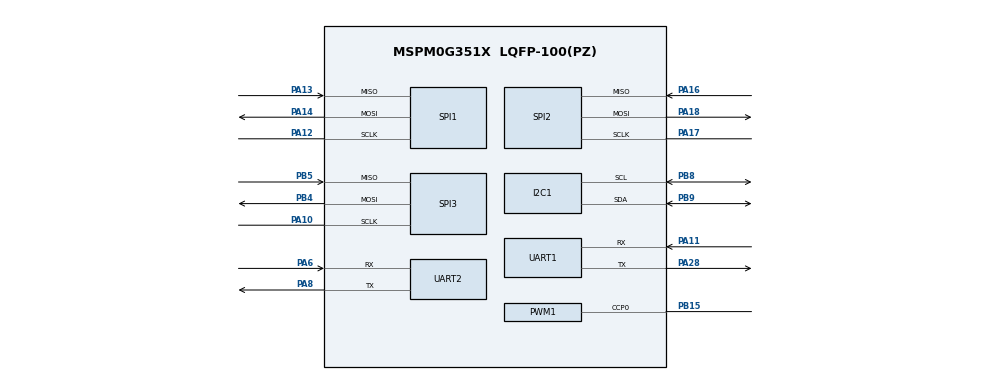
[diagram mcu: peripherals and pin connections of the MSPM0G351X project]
/**
 * @cliArgs --device "MSPM0G351X" --part "Default" --package "LQFP-100(PZ)" --product "mspm0_sdk@2.10.00.04"
 * @versions {"tool":"1.26.2+4477"}
 */

/**
 * Import the modules used in this configuration.
 */
const GPIO   = scripting.addModule("/ti/driverlib/GPIO", {}, false);
const GPIO1  = GPIO.addInstance();
const GPIO2  = GPIO.addInstance();
const GPIO3  = GPIO.addInstance();
const GPIO4  = GPIO.addInstance();
const GPIO5  = GPIO.addInstance();
const GPIO6  = GPIO.addInstance();
const GPIO7  = GPIO.addInstance();
const GPIO8  = GPIO.addInstance();
const GPIO9  = GPIO.addInstance();
const GPIO10 = GPIO.addInstance();
const GPIO11 = GPIO.addInstance();
const I2C    = scripting.addModule("/ti/driverlib/I2C", {}, false);
const I2C1   = I2C.addInstance();
const PWM    = scripting.addModule("/ti/driverlib/PWM", {}, false);
const PWM1   = PWM.addInstance();
const RTCB   = scripting.addModule("/ti/driverlib/RTCB");
const SPI    = scripting.addModule("/ti/driverlib/SPI", {}, false);
const SPI1   = SPI.addInstance();
const SPI2   = SPI.addInstance();
const SPI3   = SPI.addInstance();
const SYSCTL = scripting.addModule("/ti/driverlib/SYSCTL");
const TIMER  = scripting.addModule("/ti/driverlib/TIMER", {}, false);
const TIMER1 = TIMER.addInstance();
const TIMER2 = TIMER.addInstance();
const UART   = scripting.addModule("/ti/driverlib/UART", {}, false);
const UART1  = UART.addInstance();
const UART2  = UART.addInstance();

/**
 * Write custom configuration values to the imported modules.
 */
GPIO1.$name                                 = "BATTERY_CS";
GPIO1.associatedPins[0].$name               = "CS1";
GPIO1.associatedPins[0].initialValue        = "SET";
GPIO1.associatedPins[0].assignedPort        = "PORTB";
GPIO1.associatedPins[0].assignedPortSegment = "Upper";
GPIO1.associatedPins[0].assignedPin         = "19";

const Board = scripting.addModule("/ti/driverlib/Board", {}, false);

GPIO2.$name                                 = "SELECT_CONVERTER";
GPIO2.associatedPins[0].internalResistor    = "PULL_DOWN";
GPIO2.associatedPins[0].$name               = "PIN_0";
GPIO2.associatedPins[0].direction           = "INPUT";
GPIO2.associatedPins[0].assignedPort        = "PORTB";
GPIO2.associatedPins[0].assignedPortSegment = "Lower";
GPIO2.associatedPins[0].assignedPin         = "2";

GPIO3.$name                                 = "RECT_CS";
GPIO3.associatedPins[0].$name               = "CS2";
GPIO3.associatedPins[0].initialValue        = "SET";
GPIO3.associatedPins[0].assignedPort        = "PORTA";
GPIO3.associatedPins[0].assignedPin         = "15";
GPIO3.associatedPins[0].assignedPortSegment = "Lower";

GPIO4.$name                                 = "BAT_ALERT";
GPIO4.associatedPins[0].$name               = "PIN_1";
GPIO4.associatedPins[0].direction           = "INPUT";
GPIO4.associatedPins[0].ioStructure         = "SD";
GPIO4.associatedPins[0].assignedPort        = "PORTB";
GPIO4.associatedPins[0].interruptEn         = true;
GPIO4.associatedPins[0].polarity            = "FALL";
GPIO4.associatedPins[0].internalResistor    = "PULL_UP";
GPIO4.associatedPins[0].assignedPortSegment = "Upper";
GPIO4.associatedPins[0].assignedPin         = "18";

GPIO5.$name                              = "RECT_ALERT";
GPIO5.port                               = "PORTB";
GPIO5.portSegment                        = "Upper";
GPIO5.associatedPins[0].direction        = "INPUT";
GPIO5.associatedPins[0].ioStructure      = "SD";
GPIO5.associatedPins[0].interruptEn      = true;
GPIO5.associatedPins[0].polarity         = "FALL";
GPIO5.associatedPins[0].internalResistor = "PULL_UP";
GPIO5.associatedPins[0].assignedPin      = "17";
GPIO5.associatedPins[0].$name            = "PIN_17";

GPIO6.$name                                 = "DUMP_LOAD_RELAY";
GPIO6.associatedPins[0].assignedPortSegment = "Lower";
GPIO6.associatedPins[0].assignedPort        = "PORTA";
GPIO6.associatedPins[0].assignedPin         = "7";
GPIO6.associatedPins[0].$name               = "IN1";

GPIO7.$name                                 = "LCD";
GPIO7.associatedPins.create(6);
GPIO7.associatedPins[0].$name               = "RS";
GPIO7.associatedPins[0].assignedPort        = "PORTA";
GPIO7.associatedPins[0].assignedPortSegment = "Upper";
GPIO7.associatedPins[0].assignedPin         = "31";
GPIO7.associatedPins[1].$name               = "EN";
GPIO7.associatedPins[1].assignedPort        = "PORTA";
GPIO7.associatedPins[1].assignedPortSegment = "Lower";
GPIO7.associatedPins[1].assignedPin         = "3";
GPIO7.associatedPins[2].$name               = "D4";
GPIO7.associatedPins[2].assignedPort        = "PORTA";
GPIO7.associatedPins[2].assignedPortSegment = "Lower";
GPIO7.associatedPins[2].assignedPin         = "4";
GPIO7.associatedPins[3].$name               = "D5";
GPIO7.associatedPins[3].assignedPort        = "PORTA";
GPIO7.associatedPins[3].assignedPortSegment = "Lower";
GPIO7.associatedPins[3].assignedPin         = "5";
GPIO7.associatedPins[4].$name               = "D6";
GPIO7.associatedPins[4].assignedPortSegment = "Lower";
GPIO7.associatedPins[4].assignedPort        = "PORTB";
GPIO7.associatedPins[4].assignedPin         = "0";
GPIO7.associatedPins[5].$name               = "D7";
GPIO7.associatedPins[5].assignedPort        = "PORTB";
GPIO7.associatedPins[5].assignedPortSegment = "Lower";
GPIO7.associatedPins[5].assignedPin         = "1";

GPIO8.$name                                 = "UI_BUTTON";
GPIO8.associatedPins.create(4);
GPIO8.associatedPins[0].$name               = "NEXT";
GPIO8.associatedPins[0].direction           = "INPUT";
GPIO8.associatedPins[0].internalResistor    = "PULL_DOWN";
GPIO8.associatedPins[0].interruptEn         = true;
GPIO8.associatedPins[0].polarity            = "RISE";
GPIO8.associatedPins[0].assignedPort        = "PORTB";
GPIO8.associatedPins[0].assignedPortSegment = "Upper";
GPIO8.associatedPins[0].assignedPin         = "27";
GPIO8.associatedPins[1].$name               = "PREV";
GPIO8.associatedPins[1].direction           = "INPUT";
GPIO8.associatedPins[1].internalResistor    = "PULL_DOWN";
GPIO8.associatedPins[1].interruptEn         = true;
GPIO8.associatedPins[1].polarity            = "RISE";
GPIO8.associatedPins[1].assignedPort        = "PORTB";
GPIO8.associatedPins[1].assignedPortSegment = "Upper";
GPIO8.associatedPins[1].assignedPin         = "26";
GPIO8.associatedPins[2].internalResistor    = "PULL_DOWN";
GPIO8.associatedPins[2].$name               = "START_STOP";
GPIO8.associatedPins[2].direction           = "INPUT";
GPIO8.associatedPins[2].interruptEn         = true;
GPIO8.associatedPins[2].polarity            = "RISE";
GPIO8.associatedPins[2].assignedPort        = "PORTB";
GPIO8.associatedPins[2].assignedPortSegment = "Upper";
GPIO8.associatedPins[2].assignedPin         = "25";
GPIO8.associatedPins[3].$name               = "RECORD";
GPIO8.associatedPins[3].direction           = "INPUT";
GPIO8.associatedPins[3].internalResistor    = "PULL_DOWN";
GPIO8.associatedPins[3].interruptEn         = true;
GPIO8.associatedPins[3].polarity            = "RISE";
GPIO8.associatedPins[3].assignedPort        = "PORTA";
GPIO8.associatedPins[3].assignedPortSegment = "Upper";
GPIO8.associatedPins[3].assignedPin         = "25";

GPIO9.$name                                 = "UI_LED";
GPIO9.associatedPins.create(5);
GPIO9.associatedPins[0].$name               = "START";
GPIO9.associatedPins[0].assignedPort        = "PORTA";
GPIO9.associatedPins[0].assignedPortSegment = "Upper";
GPIO9.associatedPins[0].assignedPin         = "27";
GPIO9.associatedPins[1].$name               = "STOP";
GPIO9.associatedPins[1].assignedPort        = "PORTA";
GPIO9.associatedPins[1].assignedPortSegment = "Upper";
GPIO9.associatedPins[1].assignedPin         = "26";
GPIO9.associatedPins[2].$name               = "IS_RECORDING";
GPIO9.associatedPins[2].assignedPort        = "PORTA";
GPIO9.associatedPins[2].assignedPortSegment = "Upper";
GPIO9.associatedPins[2].assignedPin         = "24";
GPIO9.associatedPins[3].$name               = "TURBINE_OK";
GPIO9.associatedPins[3].assignedPort        = "PORTB";
GPIO9.associatedPins[3].assignedPortSegment = "Upper";
GPIO9.associatedPins[3].assignedPin         = "23";
GPIO9.associatedPins[4].$name               = "LOAD_UI_OK";
GPIO9.associatedPins[4].assignedPort        = "PORTB";
GPIO9.associatedPins[4].assignedPortSegment = "Upper";
GPIO9.associatedPins[4].assignedPin         = "24";

GPIO10.$name                                 = "SD_CS";
GPIO10.associatedPins[0].$name               = "CS";
GPIO10.associatedPins[0].initialValue        = "SET";
GPIO10.associatedPins[0].assignedPortSegment = "Lower";
GPIO10.associatedPins[0].assignedPort        = "PORTB";
GPIO10.associatedPins[0].assignedPin         = "3";

GPIO11.$name                                 = "BATTERY_RELAY";
GPIO11.associatedPins[0].assignedPort        = "PORTB";
GPIO11.associatedPins[0].assignedPortSegment = "Lower";
GPIO11.associatedPins[0].assignedPin         = "12";
GPIO11.associatedPins[0].$name               = "IN2";

I2C1.basicEnableController             = true;
I2C1.basicControllerBusSpeed           = 400000;
I2C1.$name                             = "MCP45HV51";
I2C1.peripheral.sdaPin.$assign         = "PB9";
I2C1.peripheral.sclPin.$assign         = "PB8";
I2C1.sdaPinConfig.hideOutputInversion  = scripting.forceWrite(false);
I2C1.sdaPinConfig.onlyInternalResistor = scripting.forceWrite(false);
I2C1.sdaPinConfig.passedPeripheralType = scripting.forceWrite("Digital");
I2C1.sdaPinConfig.$name                = "ti_driverlib_gpio_GPIOPinGeneric16";
I2C1.sdaPinConfig.enableConfig         = true;
I2C1.sdaPinConfig.internalResistor     = "PULL_UP";
I2C1.sclPinConfig.hideOutputInversion  = scripting.forceWrite(false);
I2C1.sclPinConfig.onlyInternalResistor = scripting.forceWrite(false);
I2C1.sclPinConfig.passedPeripheralType = scripting.forceWrite("Digital");
I2C1.sclPinConfig.$name                = "ti_driverlib_gpio_GPIOPinGeneric17";
I2C1.sclPinConfig.enableConfig         = true;
I2C1.sclPinConfig.internalResistor     = "PULL_UP";

PWM1.$name                      = "PWM_0";
PWM1.timerCount                 = 320;
PWM1.ccIndex                    = [0];
PWM1.pwmMode                    = "EDGE_ALIGN_UP";
PWM1.PWM_CHANNEL_0.$name        = "ti_driverlib_pwm_PWMTimerCC0";
PWM1.PWM_CHANNEL_0.dutyCycle    = 30;
PWM1.ccp0PinConfig.$name        = "ti_driverlib_gpio_GPIOPinGeneric5";
PWM1.peripheral.ccp0Pin.$assign = "PB15";

RTCB.calYear     = 2026;
RTCB.calMonth    = "5";
RTCB.calDOM      = 4;
RTCB.calDOW      = "4";
RTCB.enableClock = true;

SPI1.enableDMAEvent1                    = false;
SPI1.enableDMAEvent2                    = false;
SPI1.spiClkSrc                          = "MFCLK";
SPI1.spiClkDiv                          = "4";
SPI1.frameFormat                        = "MOTO3";
SPI1.chipSelect                         = [];
SPI1.phase                              = "1";
SPI1.targetBitRate                      = 500000;
SPI1.rxFifoThreshold                    = "DL_SPI_RX_FIFO_LEVEL_ONE_FRAME";
SPI1.txFifoThreshold                    = "DL_SPI_TX_FIFO_LEVEL_ONE_FRAME";
SPI1.$name                              = "INA229_RECT_SPI0";
SPI1.sclkPinConfig.direction            = scripting.forceWrite("OUTPUT");
SPI1.sclkPinConfig.onlyInternalResistor = scripting.forceWrite(false);
SPI1.sclkPinConfig.passedPeripheralType = scripting.forceWrite("Digital");
SPI1.sclkPinConfig.$name                = "ti_driverlib_gpio_GPIOPinGeneric0";
SPI1.mosiPinConfig.direction            = scripting.forceWrite("OUTPUT");
SPI1.mosiPinConfig.hideOutputInversion  = scripting.forceWrite(false);
SPI1.mosiPinConfig.onlyInternalResistor = scripting.forceWrite(false);
SPI1.mosiPinConfig.passedPeripheralType = scripting.forceWrite("Digital");
SPI1.mosiPinConfig.$name                = "ti_driverlib_gpio_GPIOPinGeneric1";
SPI1.misoPinConfig.onlyInternalResistor = scripting.forceWrite(false);
SPI1.misoPinConfig.passedPeripheralType = scripting.forceWrite("Digital");
SPI1.misoPinConfig.$name                = "ti_driverlib_gpio_GPIOPinGeneric2";
SPI1.peripheral.$assign                 = "SPI0";
SPI1.peripheral.sclkPin.$assign         = "PA12";
SPI1.peripheral.mosiPin.$assign         = "PA14";
SPI1.peripheral.misoPin.$assign         = "PA13";

SPI2.targetBitRate                      = 500000;
SPI2.frameFormat                        = "MOTO3";
SPI2.phase                              = "1";
SPI2.rxFifoThreshold                    = "DL_SPI_RX_FIFO_LEVEL_ONE_FRAME";
SPI2.txFifoThreshold                    = "DL_SPI_TX_FIFO_LEVEL_ONE_FRAME";
SPI2.$name                              = "INA229_BATTERY_SPI1";
SPI2.sclkPinConfig.$name                = "ti_driverlib_gpio_GPIOPinGeneric8";
SPI2.sclkPinConfig.direction            = scripting.forceWrite("OUTPUT");
SPI2.sclkPinConfig.onlyInternalResistor = scripting.forceWrite(false);
SPI2.sclkPinConfig.passedPeripheralType = scripting.forceWrite("Digital");
SPI2.mosiPinConfig.$name                = "ti_driverlib_gpio_GPIOPinGeneric9";
SPI2.mosiPinConfig.direction            = scripting.forceWrite("OUTPUT");
SPI2.mosiPinConfig.hideOutputInversion  = scripting.forceWrite(false);
SPI2.mosiPinConfig.onlyInternalResistor = scripting.forceWrite(false);
SPI2.mosiPinConfig.passedPeripheralType = scripting.forceWrite("Digital");
SPI2.misoPinConfig.$name                = "ti_driverlib_gpio_GPIOPinGeneric10";
SPI2.misoPinConfig.onlyInternalResistor = scripting.forceWrite(false);
SPI2.misoPinConfig.passedPeripheralType = scripting.forceWrite("Digital");
SPI2.peripheral.sclkPin.$assign         = "PA17";
SPI2.peripheral.mosiPin.$assign         = "PA18";
SPI2.peripheral.misoPin.$assign         = "PA16";

SPI3.frameFormat                        = "MOTO3";
SPI3.chipSelect                         = [];
SPI3.enableDMAEvent1                    = false;
SPI3.enableDMAEvent2                    = false;
SPI3.$name                              = "SD_CARD_SPI_2";
SPI3.sclkPinConfig.direction            = scripting.forceWrite("OUTPUT");
SPI3.sclkPinConfig.onlyInternalResistor = scripting.forceWrite(false);
SPI3.sclkPinConfig.passedPeripheralType = scripting.forceWrite("Digital");
SPI3.sclkPinConfig.$name                = "ti_driverlib_gpio_GPIOPinGeneric11";
SPI3.mosiPinConfig.direction            = scripting.forceWrite("OUTPUT");
SPI3.mosiPinConfig.hideOutputInversion  = scripting.forceWrite(false);
SPI3.mosiPinConfig.onlyInternalResistor = scripting.forceWrite(false);
SPI3.mosiPinConfig.passedPeripheralType = scripting.forceWrite("Digital");
SPI3.mosiPinConfig.$name                = "ti_driverlib_gpio_GPIOPinGeneric12";
SPI3.misoPinConfig.onlyInternalResistor = scripting.forceWrite(false);
SPI3.misoPinConfig.passedPeripheralType = scripting.forceWrite("Digital");
SPI3.misoPinConfig.$name                = "ti_driverlib_gpio_GPIOPinGeneric13";
SPI3.peripheral.sclkPin.$assign         = "PA10";
SPI3.peripheral.mosiPin.$assign         = "PB4";
SPI3.peripheral.misoPin.$assign         = "PB5";

SYSCTL.forceDefaultClkConfig = true;
SYSCTL.MFCLKEn               = true;

TIMER1.timerClkSrc        = "LFCLK";
TIMER1.timerMode          = "PERIODIC_UP";
TIMER1.timerStartTimer    = true;
TIMER1.interrupts         = ["ZERO"];
TIMER1.timerPeriod        = "50 ms";
TIMER1.$name              = "CONVERTERS_TIMER";
TIMER1.peripheral.$assign = "TIMA0";

TIMER2.timerClkSrc        = "LFCLK";
TIMER2.timerMode          = "PERIODIC_UP";
TIMER2.timerStartTimer    = true;
TIMER2.timerPeriod        = "2 s";
TIMER2.$name              = "UART_TIMER";
TIMER2.interrupts         = ["ZERO"];
TIMER2.peripheral.$assign = "TIMA1";

UART1.$name                    = "UART_0";
UART1.enableFIFO               = true;
UART1.rxFifoThreshold          = "DL_UART_RX_FIFO_LEVEL_ONE_ENTRY";
UART1.enableDMARX              = false;
UART1.enableDMATX              = false;
UART1.peripheral.$assign       = "UART0";
UART1.peripheral.rxPin.$assign = "PA11";
UART1.peripheral.txPin.$assign = "PA28";
UART1.txPinConfig.$name        = "ti_driverlib_gpio_GPIOPinGeneric3";
UART1.rxPinConfig.$name        = "ti_driverlib_gpio_GPIOPinGeneric4";

UART2.enableFIFO                       = true;
UART2.rxFifoThreshold                  = "DL_UART_RX_FIFO_LEVEL_ONE_ENTRY";
UART2.enabledInterrupts                = ["RX","RX_TIMEOUT_ERROR"];
UART2.$name                            = "UART_TURBINE";
UART2.peripheral.rxPin.$assign         = "PA6";
UART2.peripheral.txPin.$assign         = "PA8";
UART2.txPinConfig.direction            = scripting.forceWrite("OUTPUT");
UART2.txPinConfig.hideOutputInversion  = scripting.forceWrite(false);
UART2.txPinConfig.onlyInternalResistor = scripting.forceWrite(false);
UART2.txPinConfig.passedPeripheralType = scripting.forceWrite("Digital");
UART2.txPinConfig.$name                = "ti_driverlib_gpio_GPIOPinGeneric14";
UART2.rxPinConfig.hideOutputInversion  = scripting.forceWrite(false);
UART2.rxPinConfig.onlyInternalResistor = scripting.forceWrite(false);
UART2.rxPinConfig.passedPeripheralType = scripting.forceWrite("Digital");
UART2.rxPinConfig.$name                = "ti_driverlib_gpio_GPIOPinGeneric15";

const ProjectConfig              = scripting.addModule("/ti/project_config/ProjectConfig", {}, false);
ProjectConfig.migrationCondition = true;

/**
 * Pinmux solution for unlocked pins/peripherals. This ensures that minor changes to the automatic solver in a future
 * version of the tool will not impact the pinmux you originally saw.  These lines can be completely deleted in order to
 * re-solve from scratch.
 */
GPIO1.associatedPins[0].pin.$suggestSolution  = "PB19";
Board.peripheral.$suggestSolution             = "DEBUGSS";
Board.peripheral.swclkPin.$suggestSolution    = "PA20";
Board.peripheral.swdioPin.$suggestSolution    = "PA19";
GPIO2.associatedPins[0].pin.$suggestSolution  = "PB2";
GPIO3.associatedPins[0].pin.$suggestSolution  = "PA15";
GPIO4.associatedPins[0].pin.$suggestSolution  = "PB18";
GPIO5.associatedPins[0].pin.$suggestSolution  = "PB17";
GPIO6.associatedPins[0].pin.$suggestSolution  = "PA7";
GPIO7.associatedPins[0].pin.$suggestSolution  = "PA31";
GPIO7.associatedPins[1].pin.$suggestSolution  = "PA3";
GPIO7.associatedPins[2].pin.$suggestSolution  = "PA4";
GPIO7.associatedPins[3].pin.$suggestSolution  = "PA5";
GPIO7.associatedPins[4].pin.$suggestSolution  = "PB0";
GPIO7.associatedPins[5].pin.$suggestSolution  = "PB1";
GPIO8.associatedPins[0].pin.$suggestSolution  = "PB27";
GPIO8.associatedPins[1].pin.$suggestSolution  = "PB26";
GPIO8.associatedPins[2].pin.$suggestSolution  = "PB25";
GPIO8.associatedPins[3].pin.$suggestSolution  = "PA25";
GPIO9.associatedPins[0].pin.$suggestSolution  = "PA27";
GPIO9.associatedPins[1].pin.$suggestSolution  = "PA26";
GPIO9.associatedPins[2].pin.$suggestSolution  = "PA24";
GPIO9.associatedPins[3].pin.$suggestSolution  = "PB23";
GPIO9.associatedPins[4].pin.$suggestSolution  = "PB24";
GPIO10.associatedPins[0].pin.$suggestSolution = "PB3";
GPIO11.associatedPins[0].pin.$suggestSolution = "PB12";
I2C1.peripheral.$suggestSolution              = "I2C2";
PWM1.peripheral.$suggestSolution              = "TIMG7";
RTCB.peripheral.$suggestSolution              = "LFSS";
SPI2.peripheral.$suggestSolution              = "SPI1";
SPI3.peripheral.$suggestSolution              = "SPI2";
SYSCTL.peripheral.$suggestSolution            = "SYSCTL";
UART2.peripheral.$suggestSolution             = "UART1";
